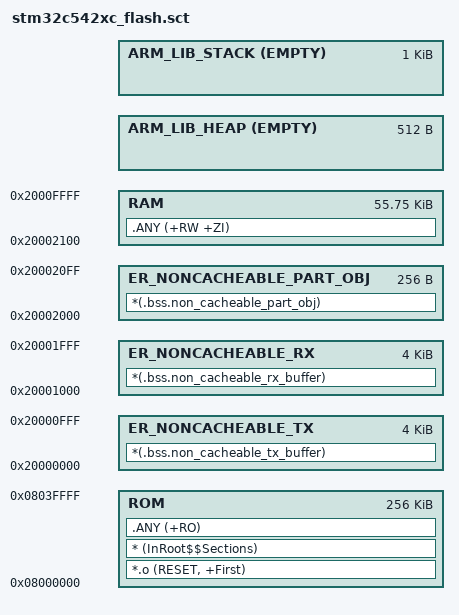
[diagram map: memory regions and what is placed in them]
#! armclang -E --target=arm-arm-none-eabi -mcpu=cortex-m33 -xc
; command above MUST be in first line (no comment above!)

; ******************************************************************************
; * @file    stm32c542xc_flash.sct
; * @brief   Linker File
; ******************************************************************************
; * @attention
; *
; * Copyright (c) 2026 STMicroelectronics.
; * All rights reserved.
; *
; * This software is licensed under terms that can be found in the LICENSE file
; * in the root directory of this software component.
; * If no LICENSE file comes with this software, it is provided AS-IS.
; *
; ******************************************************************************

#define __HEAP_SIZE 0x200
#define __STACK_SIZE 0x400


ROM 0x8000000 0x40000
{
  ROM 0x8000000 0x40000
  {
    *.o (RESET, +First)
    * (InRoot$$Sections)
    .ANY (+RO)
  }

  ; Non-cacheable TX buffer: 4 KB at start of RAM
  ER_NONCACHEABLE_TX 0x20000000 ALIGN 32 0x1000
  {
    *(.bss.non_cacheable_tx_buffer)
  }

  ; Non-cacheable RX buffer: 4 KB after TX buffer
  ER_NONCACHEABLE_RX 0x20001000 ALIGN 32 0x1000
  {
    *(.bss.non_cacheable_rx_buffer)
  }

  ; Non-cacheable Part Obj: 256 Bytes after RX buffer
  ER_NONCACHEABLE_PART_OBJ 0x20002000 ALIGN 32 0x100
  {
    *(.bss.non_cacheable_part_obj)
  }

  ; Main RAM region after non-cacheable buffers
  RAM 0x20002100 0xDF00
  {
    .ANY (+RW +ZI)
  }

  ARM_LIB_HEAP AlignExpr(+0, 8) EMPTY  __HEAP_SIZE
  {
  }

  ARM_LIB_STACK AlignExpr(+0, 8) EMPTY  __STACK_SIZE
  {
  }
}
